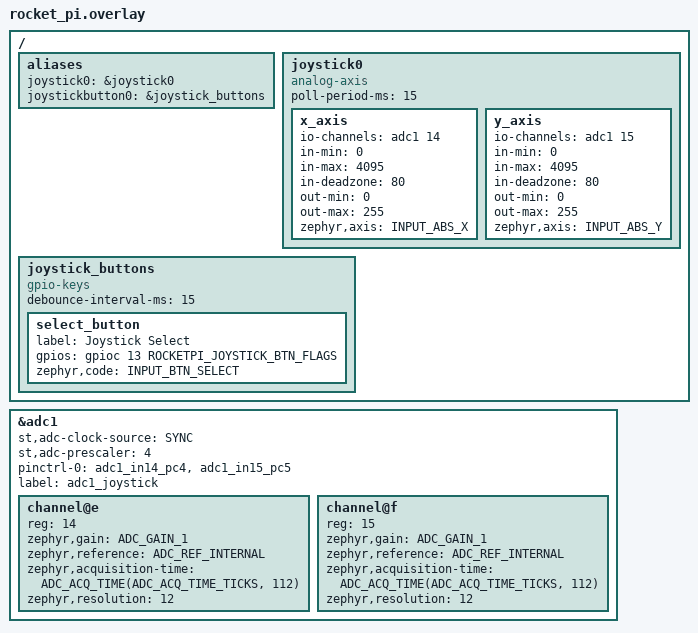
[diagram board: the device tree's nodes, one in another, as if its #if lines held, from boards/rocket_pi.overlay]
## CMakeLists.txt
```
# SPDX-License-Identifier: Apache-2.0

cmake_minimum_required(VERSION 3.20.0)
find_package(Zephyr REQUIRED HINTS $ENV{ZEPHYR_BASE})

project(adc_joystick_sample)

target_sources(app PRIVATE src/main.c)
```

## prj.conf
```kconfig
CONFIG_LOG=y
CONFIG_PRINTK=y

# Give printk/logging a bit more stack headroom
CONFIG_MAIN_STACK_SIZE=2048

CONFIG_ADC=y
CONFIG_GPIO=y

CONFIG_INPUT=y
CONFIG_INPUT_MODE_THREAD=y
CONFIG_INPUT_ANALOG_AXIS=y
CONFIG_INPUT_GPIO_KEYS=y
```

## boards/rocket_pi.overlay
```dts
#include <zephyr/dt-bindings/adc/adc.h>
#include <zephyr/dt-bindings/gpio/gpio.h>
#include <zephyr/dt-bindings/input/input-event-codes.h>


#ifdef GPIO_PULL_UP
#define ROCKETPI_JOYSTICK_BTN_FLAGS (GPIO_ACTIVE_LOW | GPIO_PULL_UP)
#else
#define ROCKETPI_JOYSTICK_BTN_FLAGS GPIO_ACTIVE_LOW
#endif

/ {
	aliases {
		joystick0 = &joystick0;
		joystickbutton0 = &joystick_buttons;
	};

	joystick0: joystick0 {
		compatible = "analog-axis";
		poll-period-ms = <15>;
		status = "okay";

		x_axis {
			io-channels = <&adc1 14>;
			in-min = <0>;
			in-max = <4095>;
			in-deadzone = <80>;
			out-min = <0>;
			out-max = <255>;
			zephyr,axis = <INPUT_ABS_X>;
		};

		y_axis {
			io-channels = <&adc1 15>;
			in-min = <0>;
			in-max = <4095>;
			in-deadzone = <80>;
			out-min = <0>;
			out-max = <255>;
			zephyr,axis = <INPUT_ABS_Y>;
		};
	};

	joystick_buttons: joystick_buttons {
		compatible = "gpio-keys";
		status = "okay";
		debounce-interval-ms = <15>;

		select_button: select_button {
			label = "Joystick Select";
			gpios = <&gpioc 13 ROCKETPI_JOYSTICK_BTN_FLAGS>;
			zephyr,code = <INPUT_BTN_SELECT>;
		};
	};
};

&adc1 {
	status = "okay";
	#address-cells = <1>;
	#size-cells = <0>;
	st,adc-clock-source = "SYNC";
	st,adc-prescaler = <4>;
	pinctrl-0 = <&adc1_in14_pc4 &adc1_in15_pc5>;
	pinctrl-names = "default";
	label = "adc1_joystick";

	/* unit-address is hex; @e/@f match io-channels 14/15 */
	channel@e {
		reg = <14>;
		zephyr,gain = "ADC_GAIN_1";
		zephyr,reference = "ADC_REF_INTERNAL";
		zephyr,acquisition-time = <ADC_ACQ_TIME(ADC_ACQ_TIME_TICKS, 112)>;
		zephyr,resolution = <12>;
	};

	channel@f {
		reg = <15>;
		zephyr,gain = "ADC_GAIN_1";
		zephyr,reference = "ADC_REF_INTERNAL";
		zephyr,acquisition-time = <ADC_ACQ_TIME(ADC_ACQ_TIME_TICKS, 112)>;
		zephyr,resolution = <12>;
	};
};
```

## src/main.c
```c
#include <zephyr/device.h>
#include <zephyr/dt-bindings/input/input-event-codes.h>
#include <zephyr/input/input.h>
#include <zephyr/kernel.h>
#include <zephyr/logging/log.h>
#include <zephyr/sys/util.h>
#include <errno.h>

LOG_MODULE_REGISTER(adc_joystick, CONFIG_LOG_DEFAULT_LEVEL);

#define JOYSTICK_ANALOG_NODE DT_ALIAS(joystick0)
#define JOYSTICK_BUTTON_NODE DT_ALIAS(joystickbutton0)

#if !DT_NODE_HAS_STATUS(JOYSTICK_ANALOG_NODE, okay)
#error "joystick0 alias is not defined or disabled in the devicetree"
#endif

#if !DT_NODE_HAS_STATUS(JOYSTICK_BUTTON_NODE, okay)
#error "joystickbutton0 alias is not defined or disabled in the devicetree"
#endif

static const char *axis_name_from_code(uint16_t code)
{
	switch (code) {
	case INPUT_ABS_X:
		return "X";
	case INPUT_ABS_Y:
		return "Y";
	default:
		return "ABS";
	}
}

static const char *button_name_from_code(uint16_t code)
{
	switch (code) {
	case INPUT_BTN_SELECT:
		return "Select";
	default:
		return "BTN";
	}
}

static void joystick_event_cb(struct input_event *evt, void *user_data)
{
	ARG_UNUSED(user_data);

	const char *dev_name = evt->dev ? evt->dev->name : "unknown";

	switch (evt->type) {
	case INPUT_EV_ABS:
		LOG_INF("[%s] %s axis: %d", dev_name,
			axis_name_from_code(evt->code), evt->value);
		break;
	case INPUT_EV_KEY:
		LOG_INF("[%s] %s %s", dev_name,
			button_name_from_code(evt->code),
			evt->value ? "pressed" : "released");
		break;
	default:
		LOG_DBG("[%s] unhandled event type %u code %u value %d",
			dev_name, evt->type, evt->code, evt->value);
		break;
	}
}

INPUT_CALLBACK_DEFINE(NULL, joystick_event_cb, NULL);

int main(void)
{
	const struct device *joystick = DEVICE_DT_GET(JOYSTICK_ANALOG_NODE);
	const struct device *buttons = DEVICE_DT_GET(JOYSTICK_BUTTON_NODE);

	if (!device_is_ready(joystick)) {
		LOG_ERR("Analog joystick device %s is not ready", joystick->name);
		return -ENODEV;
	}

	if (!device_is_ready(buttons)) {
		LOG_ERR("Joystick button device %s is not ready", buttons->name);
		return -ENODEV;
	}

	LOG_INF("ADC joystick input demo is running");

	while (true) {
		k_sleep(K_SECONDS(1));
	}
}
```
